# PIC18F14Q20 register map
Vendor: Microchip
Registers are 8-bit, read-write, reset 0x0 unless marked. A register's access mark holds for its fields unless they carry their own. Addresses are absolute, and some are shared; only a register's first bit layout is shown; [hi:lo] are bit positions; {n}, {i} and the like mark numbered series; 'fields as' and 'values as' point back to an identical list.

## ccp
0x149 CCPR1L reset not defined — (power-on value xxxxxxxx)
  [7:0] RL
0x14A CCPR1H reset not defined — (power-on value xxxxxxxx)
  [7:0] RH
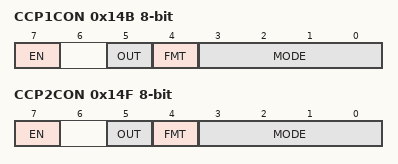
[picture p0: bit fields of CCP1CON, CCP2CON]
0x14B CCP1CON
  [7] EN, [5] OUT ro, [4] FMT, [3:0] MODE
0x14C CCP1CAP
  [2:0] CTS
0x14D CCPR2L reset not defined — (power-on value xxxxxxxx)
  [7:0] RL
0x14E CCPR2H reset not defined — (power-on value xxxxxxxx)
  [7:0] RH
0x14F CCP2CON
  [7] EN, [5] OUT ro, [4] FMT, [3:0] MODE
0x150 CCP2CAP
  [2:0] CTS

## pwm_cmp
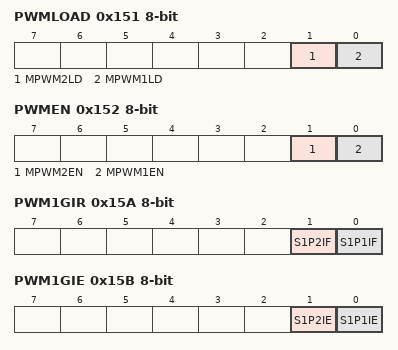
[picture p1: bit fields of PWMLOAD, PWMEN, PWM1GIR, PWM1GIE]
0x151 PWMLOAD
  [1] MPWM2LD, [0] MPWM1LD
0x152 PWMEN
  [1] MPWM2EN, [0] MPWM1EN
0x153 PWM1ERS
  [3:0] ERS
0x154 PWM1CLK
  [3:0] CLK
0x155 PWM1LDS
  [3:0] LDS
0x156 PWM1PRL
  [7:0] PRL
0x157 PWM1PRH
  [7:0] PRH
0x158 PWM1CPRE
  [7:0] CPRE
0x159 PWM1PIPOS
  [7:0] PIPOS
0x15A PWM1GIR
  [1] S1P2IF, [0] S1P1IF
0x15B PWM1GIE
  [1] S1P2IE, [0] S1P1IE
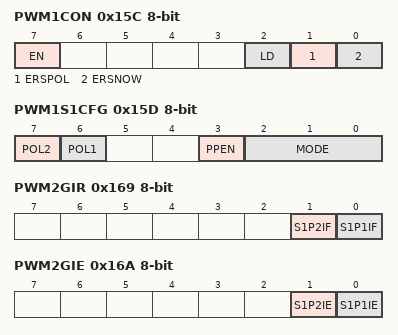
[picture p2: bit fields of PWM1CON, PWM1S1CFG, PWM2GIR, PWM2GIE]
0x15C PWM1CON
  [7] EN, [2] LD, [1] ERSPOL, [0] ERSNOW
0x15D PWM1S1CFG
  [7] POL2, [6] POL1, [3] PPEN, [2:0] MODE
0x15E PWM1S1P1L
  [7:0] S1P1L
0x15F PWM1S1P1H
  [7:0] S1P1H
0x160 PWM1S1P2L
  [7:0] S1P2L
0x161 PWM1S1P2H
  [7:0] S1P2H
0x162 PWM2ERS
  [3:0] ERS
0x163 PWM2CLK
  [3:0] CLK
0x164 PWM2LDS
  [3:0] LDS
0x165 PWM2PRL
  [7:0] PRL
0x166 PWM2PRH
  [7:0] PRH
0x167 PWM2CPRE
  [7:0] CPRE
0x168 PWM2PIPOS
  [7:0] PIPOS
0x169 PWM2GIR
  [1] S1P2IF, [0] S1P1IF
0x16A PWM2GIE
  [1] S1P2IE, [0] S1P1IE
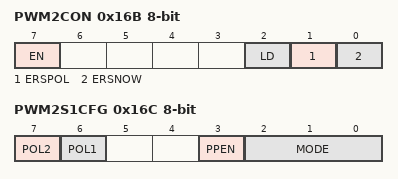
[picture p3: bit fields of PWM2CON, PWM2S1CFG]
0x16B PWM2CON
  [7] EN, [2] LD, [1] ERSPOL, [0] ERSNOW
0x16C PWM2S1CFG
  [7] POL2, [6] POL1, [3] PPEN, [2:0] MODE
0x16D PWM2S1P1L
  [7:0] S1P1L
0x16E PWM2S1P1H
  [7:0] S1P1H
0x16F PWM2S1P2L
  [7:0] S1P2L
0x170 PWM2S1P2H
  [7:0] S1P2H

## wg_ecwg
0x199 CWG1CLK
  [0] CS
0x19A CWG1ISM
  [4:0] ISM
0x19B CWG1DBR
  [5:0] DBR
0x19C CWG1DBF
  [5:0] DBF
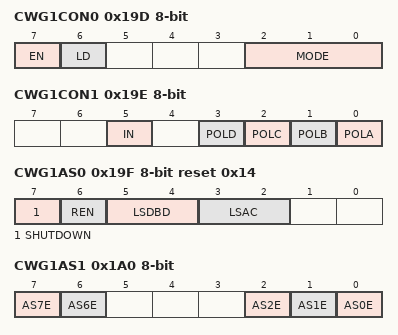
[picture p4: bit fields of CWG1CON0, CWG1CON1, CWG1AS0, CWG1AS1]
0x19D CWG1CON0
  [7] EN, [6] LD, [2:0] MODE
0x19E CWG1CON1 reset not defined — (power-on value --x-0000)
  [5] IN ro, [3] POLD, [2] POLC, [1] POLB, [0] POLA
0x19F CWG1AS0 reset 0x14
  [7] SHUTDOWN, [6] REN, [5:4] LSDBD, [3:2] LSAC
0x1A0 CWG1AS1
  [7] AS7E, [6] AS6E, [2] AS2E, [1] AS1E, [0] AS0E
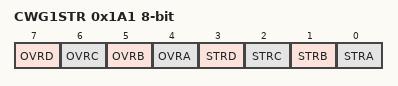
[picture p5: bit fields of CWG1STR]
0x1A1 CWG1STR
  [7] OVRD, [6] OVRC, [5] OVRB, [4] OVRA, [3] STRD, [2] STRC, [1] STRB, [0] STRA

## cla_clc
0x1A4 CLCSELECT
  [1:0] SLCT
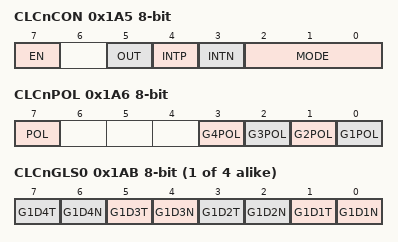
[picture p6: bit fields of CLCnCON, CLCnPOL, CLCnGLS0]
0x1A5 CLCnCON — Configurable logic cell control
  [7] EN, [5] OUT ro, [4] INTP, [3] INTN, [2:0] MODE
0x1A6 CLCnPOL reset not defined — Polarity control (power-on value 0---xxxx)
  [7] POL, [n-1] G{n}POL (n=1..4)
{0x1A7+i} CLCnSEL{i} reset not defined (i=0..3) — Input select register 1 (power-on value --xxxxxx)
  [5:0] D{i+1}S
{0x1AB+i} CLCnGLS{i} reset not defined (i=0..3) — Gate logic select register {i} (power-on value xxxxxxxx)
  [2n-1] G{i+1}D{n}T (n=1..4), [2n-2] G{i+1}D{n}N (n=1..4)

## uart_protocol
0x1AF U1RXB ro
  [7:0] RXB
0x1B0 U1RXCHK
  [7:0] RXCHK
0x1B1 U1TXB
  [7:0] TXB
0x1B2 U1TXCHK
  [7:0] TXCHK
0x1B3 U1P1L
  [7:0] P1L
{0x1B2+2i} U1P{i}H (i=1..3)
  [0] P{i}H
0x1B5 U1P2L
  [7:0] P2L
0x1B7 U1P3L reset not defined — (power-on value xxxxxxxx)
  [7:0] P3L
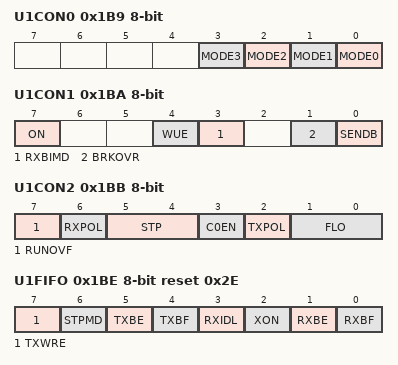
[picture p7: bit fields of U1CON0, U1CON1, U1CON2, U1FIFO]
0x1B9 U1CON0
  [n] MODE{n} (n=0..3)
0x1BA U1CON1
  [7] ON, [4] WUE, [3] RXBIMD, [1] BRKOVR, [0] SENDB
0x1BB U1CON2
  [7] RUNOVF, [6] RXPOL, [5:4] STP, [3] C0EN, [2] TXPOL, [1:0] FLO
0x1BC U1BRGL
  [7:0] BRGL
0x1BD U1BRGH
  [7:0] BRGH
0x1BE U1FIFO reset 0x2E
  [7] TXWRE, [6] STPMD, [5] TXBE, [4] TXBF ro, [3] RXIDL ro, [2] XON ro, [1] RXBE ro, [0] RXBF ro
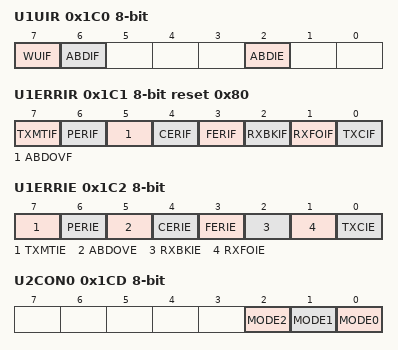
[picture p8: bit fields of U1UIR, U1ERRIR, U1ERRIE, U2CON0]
0x1C0 U1UIR
  [7] WUIF, [6] ABDIF, [2] ABDIE
0x1C1 U1ERRIR reset 0x80
  [7] TXMTIF, [6] PERIF, [5] ABDOVF, [4] CERIF, [3] FERIF, [2] RXBKIF, [1] RXFOIF, [0] TXCIF
0x1C2 U1ERRIE
  [7] TXMTIE, [6] PERIE, [5] ABDOVE, [4] CERIE, [3] FERIE, [2] RXBKIE, [1] RXFOIE, [0] TXCIE
0x1C3 U2RXB ro
  [7:0] RXB
0x1C5 U2TXB
  [7:0] TXB
0x1C7 U2P1L
  [7:0] P1L
0x1C9 U2P2L
  [7:0] P2L
0x1CB U2P3L reset not defined — (power-on value xxxxxxxx)
  [7:0] P3L
0x1CD U2CON0
  [2] MODE2, [1] MODE1, [0] MODE0
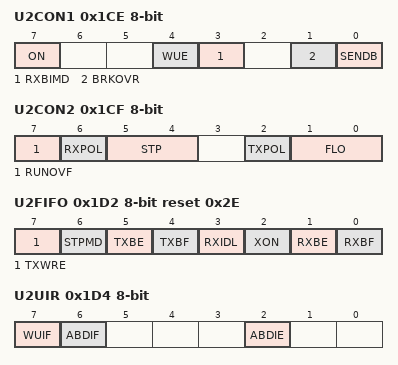
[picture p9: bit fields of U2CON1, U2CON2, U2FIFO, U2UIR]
0x1CE U2CON1
  [7] ON, [4] WUE, [3] RXBIMD, [1] BRKOVR, [0] SENDB
0x1CF U2CON2
  [7] RUNOVF, [6] RXPOL, [5:4] STP, [2] TXPOL, [1:0] FLO
0x1D0 U2BRGL
  [7:0] BRGL
0x1D1 U2BRGH
  [7:0] BRGH
0x1D2 U2FIFO reset 0x2E
  fields as U1FIFO
0x1D4 U2UIR
  [7] WUIF, [6] ABDIF, [2] ABDIE
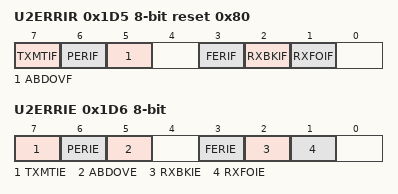
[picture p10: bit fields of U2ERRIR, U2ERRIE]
0x1D5 U2ERRIR reset 0x80
  [7] TXMTIF, [6] PERIF, [5] ABDOVF, [3] FERIF, [2] RXBKIF, [1] RXFOIF
0x1D6 U2ERRIE
  [7] TXMTIE, [6] PERIE, [5] ABDOVE, [3] FERIE, [2] RXBKIE, [1] RXFOIE
